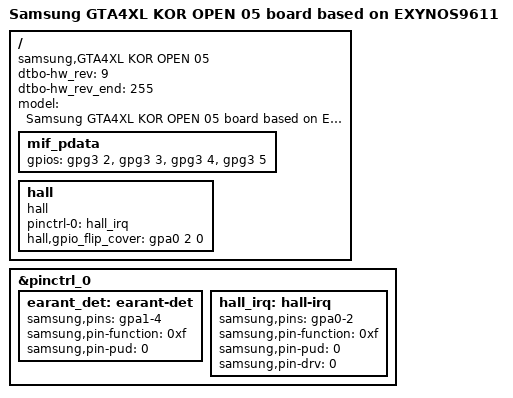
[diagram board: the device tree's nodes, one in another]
/*
 * SAMSUNG EXYNOS9610 board device tree source
 *
 * Copyright (c) 2018 Samsung Electronics Co., Ltd.
 *		http://www.samsung.com
 *
 * This program is free software; you can redistribute it and/or modify
 * it under the terms of the GNU General Public License version 2 as
 * published by the Free Software Foundation.
 */

/dts-v1/;
/plugin/;

#include "exynos9611-gta4xl_common.dtsi"
#include "battery_data_gta4xl_common.dtsi"
#include "exynos9611-gta4xl_sensorhub_00.dtsi"
#include "exynos9611-gta4xl_sound_cs47l15.dtsi"
#include "exynos9611-gta4xl_kor_open_gpio_09.dtsi"

/ {
	compatible = "samsung,GTA4XL KOR OPEN 05", "samsung,EXYNOS9611";

	dtbo-hw_rev = <9>;
	dtbo-hw_rev_end = <255>;


	fragment@model {
		target-path = "/";
		__overlay__ {
			#address-cells = <2>;
			#size-cells = <1>;

			model = "Samsung GTA4XL KOR OPEN 05 board based on EXYNOS9611";

			mif_pdata {
				/* GPIOs for HW REV */
				/* XGPIO26-AP_REV0, XGPIO27-AP_REV1, XGPIO28-AP_REV2, XGPIO29-AP_REV3 */
				gpios = <&gpg3 2 0>, <&gpg3 3 0>, <&gpg3 4 0>, <&gpg3 5 0>;
				pinctrl-names = "default";
			};

			hall {
				status = "okay";
				compatible = "hall";
				pinctrl-names = "default";
				pinctrl-0 = <&hall_irq>;
				hall,gpio_flip_cover = <&gpa0 2 0>;
			};
		}; /* end of __overlay__ */
	}; /* end of fragment */
}; /* end of root */

&pinctrl_0 {
	earant_det: earant-det {
		samsung,pins ="gpa1-4";
		samsung,pin-function = <0xf>;
		samsung,pin-pud = <0>;
	};

	hall_irq: hall-irq {
		samsung,pins = "gpa0-2";
		samsung,pin-function = <0xf>;
		samsung,pin-pud = <0>;
		samsung,pin-drv = <0>;
	};
};
